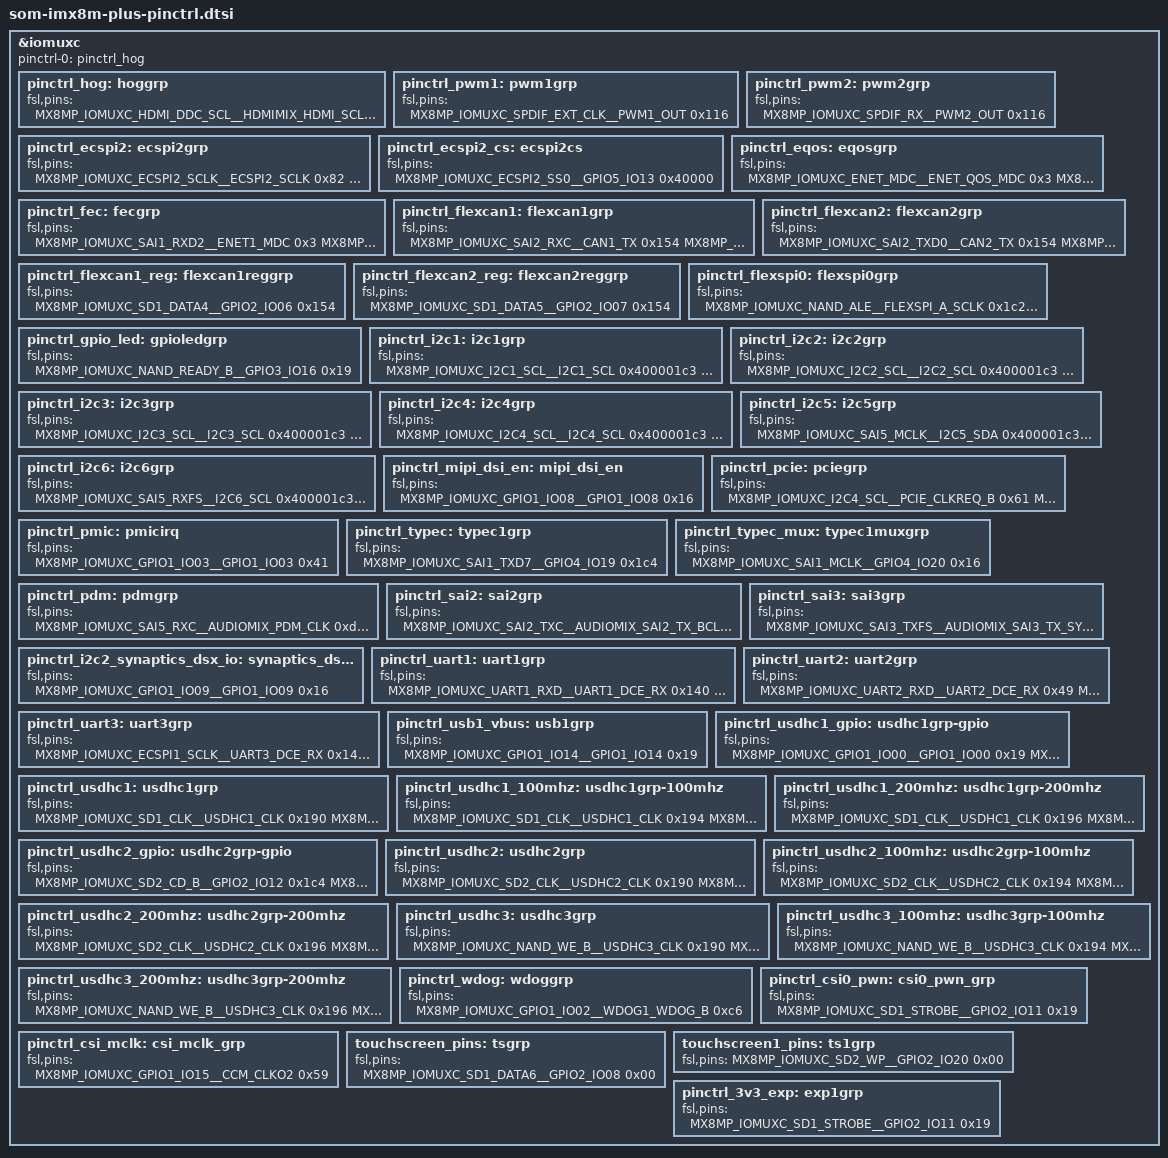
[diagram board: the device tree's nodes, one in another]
&iomuxc {
	pinctrl-names = "default";
	pinctrl-0 = <&pinctrl_hog>;

	pinctrl_hog: hoggrp {
		fsl,pins = <
			MX8MP_IOMUXC_HDMI_DDC_SCL__HDMIMIX_HDMI_SCL	0x400001c3
			MX8MP_IOMUXC_HDMI_DDC_SDA__HDMIMIX_HDMI_SDA	0x400001c3
			MX8MP_IOMUXC_HDMI_HPD__HDMIMIX_HDMI_HPD		0x40000019
			MX8MP_IOMUXC_HDMI_CEC__HDMIMIX_HDMI_CEC		0x40000019
		>;
	};

	pinctrl_pwm1: pwm1grp {
		fsl,pins = <
			MX8MP_IOMUXC_SPDIF_EXT_CLK__PWM1_OUT	0x116
		>;
	};

	pinctrl_pwm2: pwm2grp {
		fsl,pins = <
			MX8MP_IOMUXC_SPDIF_RX__PWM2_OUT		0x116
		 >;
	};

	pinctrl_ecspi2: ecspi2grp {
		fsl,pins = <
			MX8MP_IOMUXC_ECSPI2_SCLK__ECSPI2_SCLK		0x82
			MX8MP_IOMUXC_ECSPI2_MOSI__ECSPI2_MOSI		0x82
			MX8MP_IOMUXC_ECSPI2_MISO__ECSPI2_MISO		0x82
		>;
	};

	pinctrl_ecspi2_cs: ecspi2cs {
		fsl,pins = <
			MX8MP_IOMUXC_ECSPI2_SS0__GPIO5_IO13		0x40000
		>;
	};

	pinctrl_eqos: eqosgrp {
		fsl,pins = <
			MX8MP_IOMUXC_ENET_MDC__ENET_QOS_MDC	0x3
			MX8MP_IOMUXC_ENET_MDIO__ENET_QOS_MDIO	0x3
			MX8MP_IOMUXC_ENET_RD0__ENET_QOS_RGMII_RD0	0x91
			MX8MP_IOMUXC_ENET_RD1__ENET_QOS_RGMII_RD1	0x91
			MX8MP_IOMUXC_ENET_RD2__ENET_QOS_RGMII_RD2	0x91
			MX8MP_IOMUXC_ENET_RD3__ENET_QOS_RGMII_RD3	0x91
			MX8MP_IOMUXC_ENET_RXC__CCM_ENET_QOS_CLOCK_GENERATE_RX_CLK	0x91
			MX8MP_IOMUXC_ENET_RX_CTL__ENET_QOS_RGMII_RX_CTL	0x91
			MX8MP_IOMUXC_ENET_TD0__ENET_QOS_RGMII_TD0		0x1f
			MX8MP_IOMUXC_ENET_TD1__ENET_QOS_RGMII_TD1		0x1f
			MX8MP_IOMUXC_ENET_TD2__ENET_QOS_RGMII_TD2		0x1f
			MX8MP_IOMUXC_ENET_TD3__ENET_QOS_RGMII_TD3		0x1f
			MX8MP_IOMUXC_ENET_TX_CTL__ENET_QOS_RGMII_TX_CTL	0x1f
			MX8MP_IOMUXC_ENET_TXC__CCM_ENET_QOS_CLOCK_GENERATE_TX_CLK	0x1f
			MX8MP_IOMUXC_GPIO1_IO10__GPIO1_IO10     0x19
		>;
	};

	pinctrl_fec: fecgrp {
		fsl,pins = <
			MX8MP_IOMUXC_SAI1_RXD2__ENET1_MDC		0x3
			MX8MP_IOMUXC_SAI1_RXD3__ENET1_MDIO		0x3
			MX8MP_IOMUXC_SAI1_RXD4__ENET1_RGMII_RD0		0x91
			MX8MP_IOMUXC_SAI1_RXD5__ENET1_RGMII_RD1		0x91
			MX8MP_IOMUXC_SAI1_RXD6__ENET1_RGMII_RD2		0x91
			MX8MP_IOMUXC_SAI1_RXD7__ENET1_RGMII_RD3		0x91
			MX8MP_IOMUXC_SAI1_TXC__ENET1_RGMII_RXC		0x91
			MX8MP_IOMUXC_SAI1_TXFS__ENET1_RGMII_RX_CTL	0x91
			MX8MP_IOMUXC_SAI1_TXD0__ENET1_RGMII_TD0		0x1f
			MX8MP_IOMUXC_SAI1_TXD1__ENET1_RGMII_TD1		0x1f
			MX8MP_IOMUXC_SAI1_TXD2__ENET1_RGMII_TD2		0x1f
			MX8MP_IOMUXC_SAI1_TXD3__ENET1_RGMII_TD3		0x1f
			MX8MP_IOMUXC_SAI1_TXD4__ENET1_RGMII_TX_CTL	0x1f
			MX8MP_IOMUXC_SAI1_TXD5__ENET1_RGMII_TXC		0x1f
			MX8MP_IOMUXC_SAI2_TXFS__GPIO4_IO24		0x19
		>;
	};

	pinctrl_flexcan1: flexcan1grp {
		fsl,pins = <
			MX8MP_IOMUXC_SAI2_RXC__CAN1_TX          0x154
			MX8MP_IOMUXC_SAI2_TXC__CAN1_RX          0x154
		>;
	};

	pinctrl_flexcan2: flexcan2grp {
		fsl,pins = <
			MX8MP_IOMUXC_SAI2_TXD0__CAN2_TX          0x154
			MX8MP_IOMUXC_SAI2_MCLK__CAN2_RX          0x154
		>;
	};

	pinctrl_flexcan1_reg: flexcan1reggrp {
		fsl,pins = <
			MX8MP_IOMUXC_SD1_DATA4__GPIO2_IO06	0x154	/* CAN1_STBY */
		>;
	};

	pinctrl_flexcan2_reg: flexcan2reggrp {
		fsl,pins = <
			MX8MP_IOMUXC_SD1_DATA5__GPIO2_IO07	0x154	/* CAN2_STBY */
		>;
	};

	pinctrl_flexspi0: flexspi0grp {
		fsl,pins = <
			MX8MP_IOMUXC_NAND_ALE__FLEXSPI_A_SCLK		0x1c2
			MX8MP_IOMUXC_NAND_CE0_B__FLEXSPI_A_SS0_B	0x82
			MX8MP_IOMUXC_NAND_DATA00__FLEXSPI_A_DATA00	0x82
			MX8MP_IOMUXC_NAND_DATA01__FLEXSPI_A_DATA01	0x82
			MX8MP_IOMUXC_NAND_DATA02__FLEXSPI_A_DATA02	0x82
			MX8MP_IOMUXC_NAND_DATA03__FLEXSPI_A_DATA03	0x82
		>;
	};

	pinctrl_gpio_led: gpioledgrp {
		fsl,pins = <
			MX8MP_IOMUXC_NAND_READY_B__GPIO3_IO16	0x19
		>;
	};

	pinctrl_i2c1: i2c1grp {
		fsl,pins = <
			MX8MP_IOMUXC_I2C1_SCL__I2C1_SCL		0x400001c3
			MX8MP_IOMUXC_I2C1_SDA__I2C1_SDA		0x400001c3
		>;
	};

	pinctrl_i2c2: i2c2grp {
		fsl,pins = <
			MX8MP_IOMUXC_I2C2_SCL__I2C2_SCL			0x400001c3
			MX8MP_IOMUXC_I2C2_SDA__I2C2_SDA			0x400001c3
		>;
	};

	pinctrl_i2c3: i2c3grp {
		fsl,pins = <
			MX8MP_IOMUXC_I2C3_SCL__I2C3_SCL			0x400001c3
			MX8MP_IOMUXC_I2C3_SDA__I2C3_SDA			0x400001c3
		>;
	};

	pinctrl_i2c4: i2c4grp {
		fsl,pins = <
			MX8MP_IOMUXC_I2C4_SCL__I2C4_SCL			0x400001c3
			MX8MP_IOMUXC_I2C4_SDA__I2C4_SDA			0x400001c3
		>;
	};

	pinctrl_i2c5: i2c5grp {
		fsl,pins = <
			MX8MP_IOMUXC_SAI5_MCLK__I2C5_SDA		0x400001c3
			MX8MP_IOMUXC_SAI5_RXD0__I2C5_SCL		0x400001c3
		>;
	};

	pinctrl_i2c6: i2c6grp {
		fsl,pins = <
			MX8MP_IOMUXC_SAI5_RXFS__I2C6_SCL		0x400001c3
			MX8MP_IOMUXC_SAI5_RXC__I2C6_SDA			0x400001c3
		>;
	};

	pinctrl_mipi_dsi_en: mipi_dsi_en {
		fsl,pins = <
			MX8MP_IOMUXC_GPIO1_IO08__GPIO1_IO08	0x16
		>;
	};

	pinctrl_pcie: pciegrp {
		fsl,pins = <
			MX8MP_IOMUXC_I2C4_SCL__PCIE_CLKREQ_B		0x61 /* open drain, pull up */
			MX8MP_IOMUXC_SD1_DATA4__GPIO2_IO06		0x41
			MX8MP_IOMUXC_SD1_DATA5__GPIO2_IO07		0x41
		>;
	};

	pinctrl_pmic: pmicirq {
		fsl,pins = <
			MX8MP_IOMUXC_GPIO1_IO03__GPIO1_IO03	0x41
		>;
	};

	pinctrl_typec: typec1grp {
		fsl,pins = <
			MX8MP_IOMUXC_SAI1_TXD7__GPIO4_IO19	0x1c4
		>;
	};

	pinctrl_typec_mux: typec1muxgrp {
		fsl,pins = <
			MX8MP_IOMUXC_SAI1_MCLK__GPIO4_IO20	0x16
		>;
	};

	pinctrl_pdm: pdmgrp {
		fsl,pins = <
			MX8MP_IOMUXC_SAI5_RXC__AUDIOMIX_PDM_CLK		0xd6
			MX8MP_IOMUXC_SAI5_RXD0__AUDIOMIX_PDM_BIT_STREAM00	0xd6
			MX8MP_IOMUXC_SAI5_RXD1__AUDIOMIX_PDM_BIT_STREAM01	0xd6
			MX8MP_IOMUXC_SAI5_RXD2__AUDIOMIX_PDM_BIT_STREAM02	0xd6
			MX8MP_IOMUXC_SAI5_RXD3__AUDIOMIX_PDM_BIT_STREAM03	0xd6
		>;
	};

	pinctrl_sai2: sai2grp {
		fsl,pins = <
			MX8MP_IOMUXC_SAI2_TXC__AUDIOMIX_SAI2_TX_BCLK	0xd6
			MX8MP_IOMUXC_SAI2_TXFS__AUDIOMIX_SAI2_TX_SYNC	0xd6
			MX8MP_IOMUXC_SAI2_TXD0__AUDIOMIX_SAI2_TX_DATA00	0xd6
			MX8MP_IOMUXC_SAI2_RXD0__AUDIOMIX_SAI2_RX_DATA00	0xd6
		>;
	};

	pinctrl_sai3: sai3grp {
		fsl,pins = <
			MX8MP_IOMUXC_SAI3_TXFS__AUDIOMIX_SAI3_TX_SYNC	0xd6
			MX8MP_IOMUXC_SAI3_TXC__AUDIOMIX_SAI3_TX_BCLK	0xd6
			MX8MP_IOMUXC_SAI3_RXD__AUDIOMIX_SAI3_RX_DATA00	0xd6
			MX8MP_IOMUXC_SAI3_TXD__AUDIOMIX_SAI3_TX_DATA00	0xd6
			MX8MP_IOMUXC_SAI3_MCLK__AUDIOMIX_SAI3_MCLK	0xd6
			MX8MP_IOMUXC_SAI3_RXFS__GPIO4_IO28		0xd6
			MX8MP_IOMUXC_SAI3_RXC__GPIO4_IO29		0xd6
		>;
	};

	pinctrl_i2c2_synaptics_dsx_io: synaptics_dsx_iogrp {
		fsl,pins = <
			MX8MP_IOMUXC_GPIO1_IO09__GPIO1_IO09		0x16
		>;
	};

	pinctrl_uart1: uart1grp {
		fsl,pins = <
			MX8MP_IOMUXC_UART1_RXD__UART1_DCE_RX	0x140
			MX8MP_IOMUXC_UART1_TXD__UART1_DCE_TX	0x140
			MX8MP_IOMUXC_UART3_RXD__UART1_DCE_CTS	0x140
			MX8MP_IOMUXC_UART3_TXD__UART1_DCE_RTS	0x140
		>;
	};

	pinctrl_uart2: uart2grp {
		fsl,pins = <
			MX8MP_IOMUXC_UART2_RXD__UART2_DCE_RX	0x49
			MX8MP_IOMUXC_UART2_TXD__UART2_DCE_TX	0x49
		>;
	};

	pinctrl_uart3: uart3grp {
		fsl,pins = <
			MX8MP_IOMUXC_ECSPI1_SCLK__UART3_DCE_RX		0x140
			MX8MP_IOMUXC_ECSPI1_MOSI__UART3_DCE_TX		0x140
			MX8MP_IOMUXC_ECSPI1_SS0__UART3_DCE_RTS		0x140
			MX8MP_IOMUXC_ECSPI1_MISO__UART3_DCE_CTS		0x140
		>;
	};

	pinctrl_usb1_vbus: usb1grp {
		fsl,pins = <
			MX8MP_IOMUXC_GPIO1_IO14__GPIO1_IO14	0x19
		>;
	};

	pinctrl_usdhc1_gpio: usdhc1grp-gpio {
		fsl,pins = <
			/* WLAN_PD/marvell_PDn */
			MX8MP_IOMUXC_GPIO1_IO00__GPIO1_IO00	0x19
			/* WAKE_WLAN_IN/marvell_GPIO27 */
			MX8MP_IOMUXC_GPIO1_IO01__GPIO1_IO01	0x19
			/* WAKE_WLAN_OUT/marvell_GPIO14 */
			MX8MP_IOMUXC_GPIO1_IO13__GPIO1_IO13	0x19
		>;
	};

	pinctrl_usdhc1: usdhc1grp {
		fsl,pins = <
			MX8MP_IOMUXC_SD1_CLK__USDHC1_CLK	0x190
			MX8MP_IOMUXC_SD1_CMD__USDHC1_CMD	0x1d0
			MX8MP_IOMUXC_SD1_DATA0__USDHC1_DATA0	0x1d0
			MX8MP_IOMUXC_SD1_DATA1__USDHC1_DATA1	0x1d0
			MX8MP_IOMUXC_SD1_DATA2__USDHC1_DATA2	0x1d0
			MX8MP_IOMUXC_SD1_DATA3__USDHC1_DATA3	0x1d0
		>;
	};

	pinctrl_usdhc1_100mhz: usdhc1grp-100mhz {
		fsl,pins = <
			MX8MP_IOMUXC_SD1_CLK__USDHC1_CLK	0x194
			MX8MP_IOMUXC_SD1_CMD__USDHC1_CMD	0x1d4
			MX8MP_IOMUXC_SD1_DATA0__USDHC1_DATA0	0x1d4
			MX8MP_IOMUXC_SD1_DATA1__USDHC1_DATA1	0x1d4
			MX8MP_IOMUXC_SD1_DATA2__USDHC1_DATA2	0x1d4
			MX8MP_IOMUXC_SD1_DATA3__USDHC1_DATA3	0x1d4
		>;
	};

	pinctrl_usdhc1_200mhz: usdhc1grp-200mhz {
		fsl,pins = <
			MX8MP_IOMUXC_SD1_CLK__USDHC1_CLK	0x196
			MX8MP_IOMUXC_SD1_CMD__USDHC1_CMD	0x1d6
			MX8MP_IOMUXC_SD1_DATA0__USDHC1_DATA0	0x1d6
			MX8MP_IOMUXC_SD1_DATA1__USDHC1_DATA1	0x1d6
			MX8MP_IOMUXC_SD1_DATA2__USDHC1_DATA2	0x1d6
			MX8MP_IOMUXC_SD1_DATA3__USDHC1_DATA3	0x1d6
		>;
	};

	pinctrl_usdhc2_gpio: usdhc2grp-gpio {
		fsl,pins = <
			MX8MP_IOMUXC_SD2_CD_B__GPIO2_IO12 	0x1c4
			MX8MP_IOMUXC_SD2_RESET_B__GPIO2_IO19	0x41
		>;
	};

	pinctrl_usdhc2: usdhc2grp {
		fsl,pins = <
			MX8MP_IOMUXC_SD2_CLK__USDHC2_CLK	0x190
			MX8MP_IOMUXC_SD2_CMD__USDHC2_CMD	0x1d0
			MX8MP_IOMUXC_SD2_DATA0__USDHC2_DATA0	0x1d0
			MX8MP_IOMUXC_SD2_DATA1__USDHC2_DATA1	0x1d0
			MX8MP_IOMUXC_SD2_DATA2__USDHC2_DATA2	0x1d0
			MX8MP_IOMUXC_SD2_DATA3__USDHC2_DATA3	0x1d0
			MX8MP_IOMUXC_GPIO1_IO04__USDHC2_VSELECT	0xc1
		>;
	};

	pinctrl_usdhc2_100mhz: usdhc2grp-100mhz {
		fsl,pins = <
			MX8MP_IOMUXC_SD2_CLK__USDHC2_CLK	0x194
			MX8MP_IOMUXC_SD2_CMD__USDHC2_CMD	0x1d4
			MX8MP_IOMUXC_SD2_DATA0__USDHC2_DATA0	0x1d4
			MX8MP_IOMUXC_SD2_DATA1__USDHC2_DATA1	0x1d4
			MX8MP_IOMUXC_SD2_DATA2__USDHC2_DATA2	0x1d4
			MX8MP_IOMUXC_SD2_DATA3__USDHC2_DATA3	0x1d4
			MX8MP_IOMUXC_GPIO1_IO04__USDHC2_VSELECT 0xc1
		>;
	};

	pinctrl_usdhc2_200mhz: usdhc2grp-200mhz {
		fsl,pins = <
			MX8MP_IOMUXC_SD2_CLK__USDHC2_CLK	0x196
			MX8MP_IOMUXC_SD2_CMD__USDHC2_CMD	0x1d6
			MX8MP_IOMUXC_SD2_DATA0__USDHC2_DATA0	0x1d6
			MX8MP_IOMUXC_SD2_DATA1__USDHC2_DATA1	0x1d6
			MX8MP_IOMUXC_SD2_DATA2__USDHC2_DATA2	0x1d6
			MX8MP_IOMUXC_SD2_DATA3__USDHC2_DATA3	0x1d6
			MX8MP_IOMUXC_GPIO1_IO04__USDHC2_VSELECT 0xc1
		>;
	};

	pinctrl_usdhc3: usdhc3grp {
		fsl,pins = <
			MX8MP_IOMUXC_NAND_WE_B__USDHC3_CLK	0x190
			MX8MP_IOMUXC_NAND_WP_B__USDHC3_CMD	0x1d0
			MX8MP_IOMUXC_NAND_DATA04__USDHC3_DATA0	0x1d0
			MX8MP_IOMUXC_NAND_DATA05__USDHC3_DATA1	0x1d0
			MX8MP_IOMUXC_NAND_DATA06__USDHC3_DATA2	0x1d0
			MX8MP_IOMUXC_NAND_DATA07__USDHC3_DATA3	0x1d0
			MX8MP_IOMUXC_NAND_RE_B__USDHC3_DATA4	0x1d0
			MX8MP_IOMUXC_NAND_CE2_B__USDHC3_DATA5	0x1d0
			MX8MP_IOMUXC_NAND_CE3_B__USDHC3_DATA6	0x1d0
			MX8MP_IOMUXC_NAND_CLE__USDHC3_DATA7	0x1d0
			MX8MP_IOMUXC_NAND_CE1_B__USDHC3_STROBE	0x190
		>;
	};

	pinctrl_usdhc3_100mhz: usdhc3grp-100mhz {
		fsl,pins = <
			MX8MP_IOMUXC_NAND_WE_B__USDHC3_CLK	0x194
			MX8MP_IOMUXC_NAND_WP_B__USDHC3_CMD	0x1d4
			MX8MP_IOMUXC_NAND_DATA04__USDHC3_DATA0	0x1d4
			MX8MP_IOMUXC_NAND_DATA05__USDHC3_DATA1	0x1d4
			MX8MP_IOMUXC_NAND_DATA06__USDHC3_DATA2	0x1d4
			MX8MP_IOMUXC_NAND_DATA07__USDHC3_DATA3	0x1d4
			MX8MP_IOMUXC_NAND_RE_B__USDHC3_DATA4	0x1d4
			MX8MP_IOMUXC_NAND_CE2_B__USDHC3_DATA5	0x1d4
			MX8MP_IOMUXC_NAND_CE3_B__USDHC3_DATA6	0x1d4
			MX8MP_IOMUXC_NAND_CLE__USDHC3_DATA7	0x1d4
			MX8MP_IOMUXC_NAND_CE1_B__USDHC3_STROBE	0x194
		>;
	};

	pinctrl_usdhc3_200mhz: usdhc3grp-200mhz {
		fsl,pins = <
			MX8MP_IOMUXC_NAND_WE_B__USDHC3_CLK	0x196
			MX8MP_IOMUXC_NAND_WP_B__USDHC3_CMD	0x1d6
			MX8MP_IOMUXC_NAND_DATA04__USDHC3_DATA0	0x1d6
			MX8MP_IOMUXC_NAND_DATA05__USDHC3_DATA1	0x1d6
			MX8MP_IOMUXC_NAND_DATA06__USDHC3_DATA2	0x1d6
			MX8MP_IOMUXC_NAND_DATA07__USDHC3_DATA3	0x1d6
			MX8MP_IOMUXC_NAND_RE_B__USDHC3_DATA4	0x1d6
			MX8MP_IOMUXC_NAND_CE2_B__USDHC3_DATA5	0x1d6
			MX8MP_IOMUXC_NAND_CE3_B__USDHC3_DATA6	0x1d6
			MX8MP_IOMUXC_NAND_CLE__USDHC3_DATA7	0x1d6
			MX8MP_IOMUXC_NAND_CE1_B__USDHC3_STROBE	0x196
		>;
	};

	pinctrl_wdog: wdoggrp {
		fsl,pins = <
			MX8MP_IOMUXC_GPIO1_IO02__WDOG1_WDOG_B	0xc6
		>;
	};

	pinctrl_csi0_pwn: csi0_pwn_grp {
		fsl,pins = <
			MX8MP_IOMUXC_SD1_STROBE__GPIO2_IO11	0x19
		>;
	};

	pinctrl_csi_mclk: csi_mclk_grp {
		fsl,pins = <
			MX8MP_IOMUXC_GPIO1_IO15__CCM_CLKO2	0x59
		>;
	};

	touchscreen_pins: tsgrp {
		fsl,pins = <
			MX8MP_IOMUXC_SD1_DATA6__GPIO2_IO08	0x00
		>;
	};

	touchscreen1_pins: ts1grp {
		fsl,pins = <
			MX8MP_IOMUXC_SD2_WP__GPIO2_IO20		0x00
		>;
	};

	pinctrl_3v3_exp: exp1grp {
		fsl,pins = <
			MX8MP_IOMUXC_SD1_STROBE__GPIO2_IO11	0x19
		>;
	};
};
